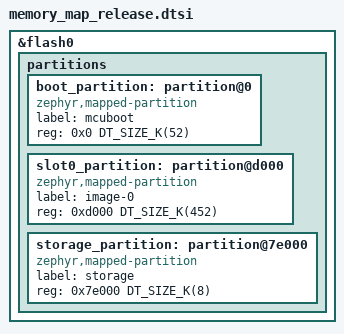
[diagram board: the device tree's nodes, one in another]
/*
 * Copyright (c) 2026 Nordic Semiconductor ASA
 *
 * SPDX-License-Identifier: LicenseRef-Nordic-5-Clause
 */

&flash0 {
	/delete-node/ partitions;

	partitions {
		#address-cells = <1>;
		#size-cells = <1>;
		ranges;

		boot_partition: partition@0 {
			compatible = "zephyr,mapped-partition";
			label = "mcuboot";
			reg = <0x0 DT_SIZE_K(52)>;
		};

		slot0_partition: partition@d000 {
			compatible = "zephyr,mapped-partition";
			label = "image-0";
			reg = <0xd000 DT_SIZE_K(452)>;
		};

		storage_partition: partition@7e000 {
			compatible = "zephyr,mapped-partition";
			label = "storage";
			reg = <0x7e000 DT_SIZE_K(8)>;
		};
	};
};
